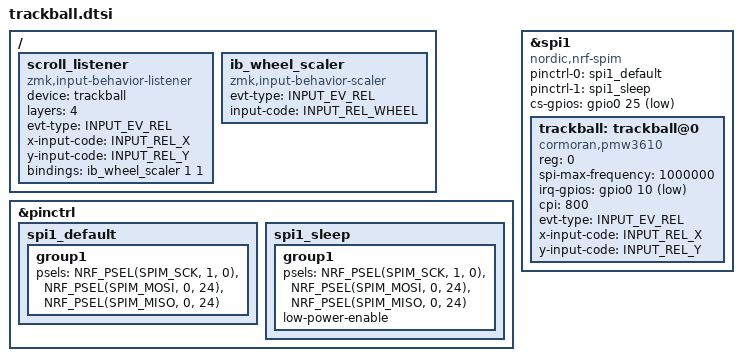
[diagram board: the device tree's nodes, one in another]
#include <zephyr/dt-bindings/input/input-event-codes.h>

&pinctrl {
    spi1_default: spi1_default {
        group1 {
                psels = <NRF_PSEL(SPIM_SCK, 1, 0)>,
                <NRF_PSEL(SPIM_MOSI, 0, 24)>,
                <NRF_PSEL(SPIM_MISO, 0, 24)>;
        };
    };

    spi1_sleep: spi1_sleep {
        group1 {
            psels = <NRF_PSEL(SPIM_SCK, 1, 0)>,
                <NRF_PSEL(SPIM_MOSI, 0, 24)>,
                <NRF_PSEL(SPIM_MISO, 0, 24)>;
            low-power-enable;
        };
    };
};

&spi1 {
    status = "okay";
    compatible = "nordic,nrf-spim";
    pinctrl-0 = <&spi1_default>;
    pinctrl-1 = <&spi1_sleep>;
    pinctrl-names = "default", "sleep";
    cs-gpios = <&gpio0 25 GPIO_ACTIVE_LOW>;

    trackball: trackball@0 {
        status = "okay";
        compatible = "cormoran,pmw3610";
        reg = <0>;
        // [保留] 降頻防暴衝
        spi-max-frequency = <1000000>;
        irq-gpios = <&gpio0 10 (GPIO_ACTIVE_LOW | GPIO_PULL_UP)>;
        cpi = <800>;
        evt-type = <INPUT_EV_REL>;
        x-input-code = <INPUT_REL_X>;
        y-input-code = <INPUT_REL_Y>;
    };
};

// [新增] 將滾輪轉換模組放在這裡，它只會跟著右手軌跡球一起編譯！
/ {
    scroll_listener: scroll_listener {
        compatible = "zmk,input-behavior-listener";
        device = <&trackball>;
        layers = <4>;
        evt-type = <INPUT_EV_REL>;
        x-input-code = <INPUT_REL_X>;
        y-input-code = <INPUT_REL_Y>;
        bindings = <&ib_wheel_scaler 1 1>;
    };

    ib_wheel_scaler: ib_wheel_scaler {
        compatible = "zmk,input-behavior-scaler";
        #binding-cells = <2>;
        evt-type = <INPUT_EV_REL>;
        input-code = <INPUT_REL_WHEEL>;
    };
};
